# AUX_AIODIO register map
Vendor: Texas Instruments
Peripheral module from a debugger description file (folder CC2650).
Registers are 32-bit, access per field, reset 0x0 unless marked. A register's access mark holds for its fields unless they carry their own. Offsets are as the file gives them; lines under a group give offsets from that group; [hi:lo] are bit positions; {n}, {i} and the like mark numbered series; 'fields as' and 'values as' point back to an identical list; <NAME> marks a mode.

## AUX_AIODIO — AUX Analog/Digital Input Output Controller
0x00 GPIODOUT — General Purpose Input/Output Data Out This register is used to set data on the pads assigned to AUX
  [7:0] IO7_0 rw — Output values for AUXIO0 through AUXIO7 (for AIODIO0) or AUXIO8 through AUXIO15 (for AIODIO1).
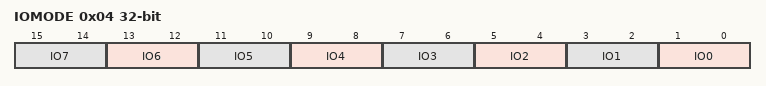
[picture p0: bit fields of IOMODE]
0x04 IOMODE — Input Output Mode Controls pull-up pull-down and output mode for the IO pins assigned to AUX
  [2n+1:2n] IO{n} rw (n=0..7) — Selects mode for AUXIO{n} (for AIODIO0) or AUXIO{n+8} (for AIODIO1).
    3=OPEN_SOURCE (Open-source: The pin is driven high when the corresponding GPIODOUT bit is 1, and otherwise tri-stated or pulled depending on the corresponding IOC configuration.); 2=OPEN_DRAIN (Open-drain: The pin is driven low when the corresponding GPIODOUT bit is 0, and otherwise tri-stated or pulled depending on the corresponding IOC configuration.); 1=IN (Digital input with GPIODIE bit {n} = 1 Analog input/output with GPIODIE bit {n} = 0); 0=OUT (Output)
0x08 GPIODIN ro — General Purpose Input Output Data In
  [7:0] IO7_0 — Input values for AUXIO0 through AUXIO7 (for AIODIO0) or AUXIO8 through AUXIO15 (for AIODIO1).
0x0C GPIODOUTSET — General Purpose Input Output Data Out Set Strobes for setting output data register bits
  [7:0] IO7_0 rw — Writing 1(s) to one or more bit positions sets the corresponding bit(s) in GPIODOUT. Read value is 0x00.
0x10 GPIODOUTCLR — General Purpose Input Output Data Out Clear Strobes for clearing output data register bits
  [7:0] IO7_0 rw — Writing 1(s) to one or more bit positions clears the corresponding bit(s) in GPIODOUT. Read value is 0x00.
0x14 GPIODOUTTGL — General Purpose Input Output Data Out Toggle Strobes for toggling output data register bits
  [7:0] IO7_0 rw — Writing 1(s) to one or more bit positions toggles the corresponding bit(s) in GPIODOUT. Read value is 0x00.
0x18 GPIODIE — General Purpose Input Output Input Enable
  [7:0] IO7_0 rw — Enables (1) or disables (0) digital input buffers for each AUX I/O pin. Input buffers must be enabled to allow reading pin values through GPIODIN. Input buffers must be disabled for analog input or floating pins to avoid current leakage.
